AUTOSAR XML (schema 00046)
package /RunnableLab
  sender receiver interface SRI_Output
    data SumResult: type=uint32
  sender receiver interface SRI_Input
    data Val1: type=uint16
    data Val2: type=uint16
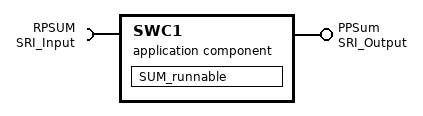
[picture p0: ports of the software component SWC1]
  application sw component type SWC1
    provide port PPSum: provided-interface=SRI_Output
    require port RPSUM: required-interface=SRI_Input
    behavior SWC1_Beh
      runnable SUM_runnable: symbol=SUM
        data-read-access:
          access VAL1_DATA: accessed-variable=RPSUM.Val1
          access VAL2_DATA: accessed-variable=RPSUM.Val2
        data-write-access:
          access SUMResult_Data: accessed-variable=PPSum.SumResult
